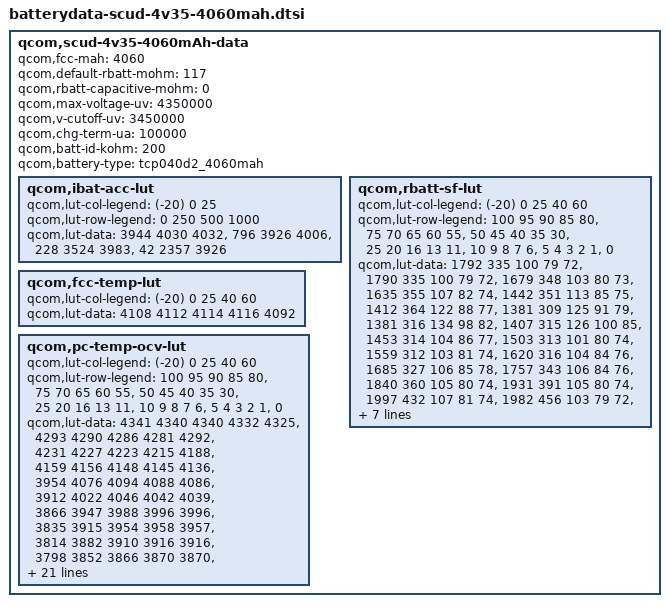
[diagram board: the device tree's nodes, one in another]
qcom,scud-4v35-4060mAh-data {
	qcom,fcc-mah = <4060>;
	qcom,default-rbatt-mohm = <117>;
	qcom,rbatt-capacitive-mohm = <0>;
	qcom,max-voltage-uv = <4350000>;
	qcom,v-cutoff-uv = <3450000>;
	qcom,chg-term-ua = <100000>;
	qcom,batt-id-kohm = <200>;
	qcom,battery-type = "tcp040d2_4060mah";

	qcom,ibat-acc-lut {
		qcom,lut-col-legend = <(-20) 0 25>;
		qcom,lut-row-legend = <0 250 500 1000>;
		qcom,lut-data = <3944 4030 4032>,
								<796 3926 4006>,
								<228 3524 3983>,
								<42 2357 3926>;
	};

	qcom,rbatt-sf-lut {
		qcom,lut-col-legend = <(-20) 0 25 40 60>;
		qcom,lut-row-legend = <100 95 90 85 80>,
				<75 70 65 60 55>,
				<50 45 40 35 30>,
				<25 20 16 13 11>,
				<10 9 8 7 6>,
				<5 4 3 2 1>,
				<0>;
		qcom,lut-data = <1792 335 100 79 72>,
				<1790 335 100 79 72>,
				<1679 348 103 80 73>,
				<1635 355 107 82 74>,
				<1442 351 113 85 75>,
				<1412 364 122 88 77>,
				<1381 309 125 91 79>,
				<1381 316 134 98 82>,
				<1407 315 126 100 85>,
				<1453 314 104 86 77>,
				<1503 313 101 80 74>,
				<1559 312 103 81 74>,
				<1620 316 104 84 76>,
				<1685 327 106 85 78>,
				<1757 343 106 84 76>,
				<1840 360 105 80 74>,
				<1931 391 105 80 74>,
				<1997 432 107 81 74>,
				<1982 456 103 79 72>,
				<1957 462 104 81 74>,
				<2074 477 107 83 74>,
				<2255 494 109 85 76>,
				<2455 510 115 86 79>,
				<2668 527 119 88 82>,
				<2944 544 124 91 81>,
				<3312 558 121 86 75>,
				<3838 580 118 85 76>,
				<4843 611 120 87 79>,
				<7437 658 129 94 92>,
				<14874 1207 189 144 185>,
				<29747 2414 378 289 369>;
	};

	qcom,fcc-temp-lut {
		qcom,lut-col-legend = <(-20) 0 25 40 60>;
		qcom,lut-data = <4108 4112 4114 4116 4092>;
	};

	qcom,pc-temp-ocv-lut {
		qcom,lut-col-legend = <(-20) 0 25 40 60>;
		qcom,lut-row-legend = <100 95 90 85 80>,
				<75 70 65 60 55>,
				<50 45 40 35 30>,
				<25 20 16 13 11>,
				<10 9 8 7 6>,
				<5 4 3 2 1>,
				<0>;
		qcom,lut-data = <4341 4340 4340 4332 4325>,
				<4293 4290 4286 4281 4292>,
				<4231 4227 4223 4215 4188>,
				<4159 4156 4148 4145 4136>,
				<3954 4076 4094 4088 4086>,
				<3912 4022 4046 4042 4039>,
				<3866 3947 3988 3996 3996>,
				<3835 3915 3954 3958 3957>,
				<3814 3882 3910 3916 3916>,
				<3798 3852 3866 3870 3870>,
				<3783 3824 3837 3839 3839>,
				<3768 3800 3816 3817 3817>,
				<3752 3782 3797 3799 3798>,
				<3737 3768 3782 3784 3782>,
				<3720 3753 3770 3768 3763>,
				<3700 3737 3756 3750 3738>,
				<3676 3722 3738 3730 3716>,
				<3652 3712 3712 3705 3690>,
				<3631 3705 3692 3683 3672>,
				<3614 3697 3689 3681 3670>,
				<3603 3692 3688 3680 3668>,
				<3590 3686 3686 3679 3668>,
				<3576 3678 3685 3678 3666>,
				<3557 3668 3683 3675 3664>,
				<3534 3650 3675 3668 3651>,
				<3504 3624 3650 3641 3616>,
				<3466 3586 3604 3592 3564>,
				<3412 3530 3538 3525 3492>,
				<3336 3444 3444 3430 3393>,
				<3150 3210 3211 3200 3162>,
				<3000 3013 3028 3008 3000>;
	};
};
